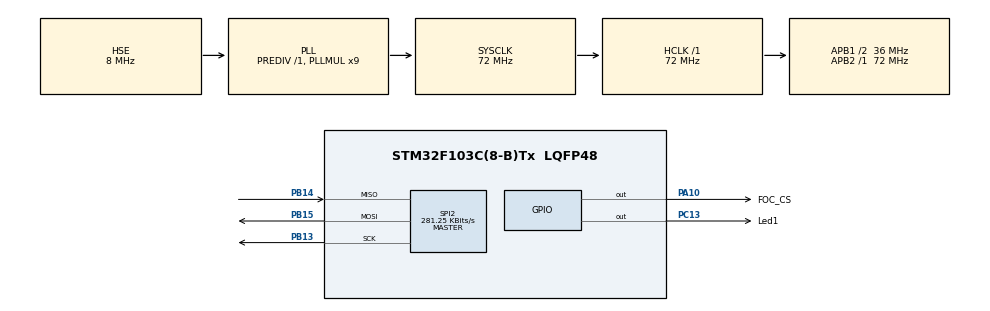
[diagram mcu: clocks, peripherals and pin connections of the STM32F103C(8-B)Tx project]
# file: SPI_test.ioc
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Mcu.Family=STM32F1
Mcu.Name=STM32F103C(8-B)Tx
Mcu.Package=LQFP48
NVIC.PriorityGroup=NVIC_PRIORITYGROUP_4
PA10.GPIO_Label=FOC_CS
PA10.Signal=GPIO_Output
PA13.Mode=Trace_Asynchronous_SW
PA13.Signal=SYS_JTMS-SWDIO
PA14.Mode=Trace_Asynchronous_SW
PA14.Signal=SYS_JTCK-SWCLK
PB13.Mode=Full_Duplex_Master
PB13.Signal=SPI2_SCK
PB14.Mode=Full_Duplex_Master
PB14.Signal=SPI2_MISO
PB15.Mode=Full_Duplex_Master
PB15.Signal=SPI2_MOSI
PB3.Mode=Trace_Asynchronous_SW
PB3.Signal=SYS_JTDO-TRACESWO
PC13-TAMPER-RTC.GPIO_Label=Led1
PC13-TAMPER-RTC.Signal=GPIO_Output
PC14-OSC32_IN.Mode=LSE-External-Oscillator
PC14-OSC32_IN.Signal=RCC_OSC32_IN
PC15-OSC32_OUT.Mode=LSE-External-Oscillator
PC15-OSC32_OUT.Signal=RCC_OSC32_OUT
PD0-OSC_IN.Mode=HSE-External-Oscillator
PD0-OSC_IN.Signal=RCC_OSC_IN
PD1-OSC_OUT.Mode=HSE-External-Oscillator
PD1-OSC_OUT.Signal=RCC_OSC_OUT
ProjectManager.HeapSize=0x200
ProjectManager.StackSize=0x400
ProjectManager.TargetToolchain=STM32CubeIDE
RCC.AHBFreq_Value=72000000
RCC.APB1CLKDivider=RCC_HCLK_DIV2
RCC.APB1Freq_Value=36000000
RCC.APB1TimFreq_Value=72000000
RCC.APB2Freq_Value=72000000
RCC.APB2TimFreq_Value=72000000
RCC.HCLKFreq_Value=72000000
RCC.PLLMUL=RCC_PLL_MUL9
RCC.PLLSourceVirtual=RCC_PLLSOURCE_HSE
RCC.SYSCLKFreq_VALUE=72000000
RCC.SYSCLKSource=RCC_SYSCLKSOURCE_PLLCLK
RCC.USBFreq_Value=72000000
SPI2.BaudRatePrescaler=SPI_BAUDRATEPRESCALER_128
SPI2.CLKPhase=SPI_PHASE_2EDGE
SPI2.CLKPolarity=SPI_POLARITY_HIGH
SPI2.CalculateBaudRate=281.25 KBits/s
SPI2.Direction=SPI_DIRECTION_2LINES
SPI2.Mode=SPI_MODE_MASTER
SPI2.VirtualType=VM_MASTER
board=custom

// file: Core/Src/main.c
/* USER CODE BEGIN Header */
/**
  ******************************************************************************
  * @file           : main.c
  * @brief          : Main program body
  ******************************************************************************
  * @attention
  *
  * <h2><center>&copy; Copyright (c) 2020 STMicroelectronics.
  * All rights reserved.</center></h2>
  *
  * This software component is licensed by ST under BSD 3-Clause license,
  * the "License"; You may not use this file except in compliance with the
  * License. You may obtain a copy of the License at:
  *                        opensource.org/licenses/BSD-3-Clause
  *
  ******************************************************************************
  */
/* USER CODE END Header */

#include "main.h"

/* USER CODE BEGIN Includes */
#include <stdio.h>

/* USER CODE END Includes */

SPI_HandleTypeDef hspi2;

void SystemClock_Config(void);
static void MX_GPIO_Init(void);
static void MX_SPI2_Init(void);

int main(void)
{

  /* MCU Configuration--------------------------------------------------------*/

  /* Reset of all peripherals, Initializes the Flash interface and the Systick. */
  HAL_Init();

  /* USER CODE BEGIN Init */

  HAL_GPIO_WritePin(FOC_CS_GPIO_Port, FOC_CS_Pin, SET);
  /* USER CODE END Init */

  /* Configure the system clock */
  SystemClock_Config();

  /* Initialize all configured peripherals */
  MX_GPIO_Init();
  MX_SPI2_Init();
  /* USER CODE BEGIN 2 */
  uint8_t aux[5], aux2[1], str[5];
     aux[0]=0b10000001;
     for(int i=1; i<=4; i++){
   	  aux[i]=0b00000000;
     }
     aux2[0]=0b00000000;

  for(int i=0; i<4; i++){
  	  printf("aux %d - %d\n", i, aux[i]);
    }
  /* USER CODE END 2 */

  /* Infinite loop */
  while (1)
  {

    /* USER CODE BEGIN 3 */

	  HAL_GPIO_TogglePin(Led1_GPIO_Port, Led1_Pin);
	  HAL_Delay(50);

	  HAL_GPIO_WritePin(FOC_CS_GPIO_Port, FOC_CS_Pin, RESET);
	  HAL_SPI_Transmit(&hspi2, aux, 5, 1000);
	  HAL_GPIO_WritePin(FOC_CS_GPIO_Port, FOC_CS_Pin, SET);
	  //HAL_Delay(1);

	  HAL_GPIO_WritePin(FOC_CS_GPIO_Port, FOC_CS_Pin, RESET);
	  HAL_SPI_Transmit(&hspi2, aux2, 1, 1000);
	  //HAL_Delay(1);
	  HAL_SPI_Receive(&hspi2, str, 4, 1000);
	  HAL_GPIO_WritePin(FOC_CS_GPIO_Port, FOC_CS_Pin, SET);
	  //HAL_SPI_Receive(&hspi2, str, 4, 200);
	  printf("Aquiii\n");
	  printf("%d %d %d %d\n", str[0], str[1], str[2], str[3]);

  }
  /* USER CODE END 3 */
}

void SystemClock_Config(void)
{
  RCC_OscInitTypeDef RCC_OscInitStruct = {0};
  RCC_ClkInitTypeDef RCC_ClkInitStruct = {0};

  /** Initializes the CPU, AHB and APB busses clocks
  */
  RCC_OscInitStruct.OscillatorType = RCC_OSCILLATORTYPE_HSE;
  RCC_OscInitStruct.HSEState = RCC_HSE_ON;
  RCC_OscInitStruct.HSEPredivValue = RCC_HSE_PREDIV_DIV1;
  RCC_OscInitStruct.HSIState = RCC_HSI_ON;
  RCC_OscInitStruct.PLL.PLLState = RCC_PLL_ON;
  RCC_OscInitStruct.PLL.PLLSource = RCC_PLLSOURCE_HSE;
  RCC_OscInitStruct.PLL.PLLMUL = RCC_PLL_MUL9;
  if (HAL_RCC_OscConfig(&RCC_OscInitStruct) != HAL_OK)
  {
    Error_Handler();
  }
  /** Initializes the CPU, AHB and APB busses clocks
  */
  RCC_ClkInitStruct.ClockType = RCC_CLOCKTYPE_HCLK|RCC_CLOCKTYPE_SYSCLK
                              |RCC_CLOCKTYPE_PCLK1|RCC_CLOCKTYPE_PCLK2;
  RCC_ClkInitStruct.SYSCLKSource = RCC_SYSCLKSOURCE_PLLCLK;
  RCC_ClkInitStruct.AHBCLKDivider = RCC_SYSCLK_DIV1;
  RCC_ClkInitStruct.APB1CLKDivider = RCC_HCLK_DIV2;
  RCC_ClkInitStruct.APB2CLKDivider = RCC_HCLK_DIV1;

  if (HAL_RCC_ClockConfig(&RCC_ClkInitStruct, FLASH_LATENCY_2) != HAL_OK)
  {
    Error_Handler();
  }
}

static void MX_SPI2_Init(void)
{

  /* SPI2 parameter configuration*/
  hspi2.Instance = SPI2;
  hspi2.Init.Mode = SPI_MODE_MASTER;
  hspi2.Init.Direction = SPI_DIRECTION_2LINES;
  hspi2.Init.DataSize = SPI_DATASIZE_8BIT;
  hspi2.Init.CLKPolarity = SPI_POLARITY_HIGH;
  hspi2.Init.CLKPhase = SPI_PHASE_2EDGE;
  hspi2.Init.NSS = SPI_NSS_SOFT;
  hspi2.Init.BaudRatePrescaler = SPI_BAUDRATEPRESCALER_128;
  hspi2.Init.FirstBit = SPI_FIRSTBIT_MSB;
  hspi2.Init.TIMode = SPI_TIMODE_DISABLE;
  hspi2.Init.CRCCalculation = SPI_CRCCALCULATION_DISABLE;
  hspi2.Init.CRCPolynomial = 10;
  if (HAL_SPI_Init(&hspi2) != HAL_OK)
  {
    Error_Handler();
  }

}

static void MX_GPIO_Init(void)
{
  GPIO_InitTypeDef GPIO_InitStruct = {0};

  /* GPIO Ports Clock Enable */
  __HAL_RCC_GPIOC_CLK_ENABLE();
  __HAL_RCC_GPIOD_CLK_ENABLE();
  __HAL_RCC_GPIOB_CLK_ENABLE();
  __HAL_RCC_GPIOA_CLK_ENABLE();

  /*Configure GPIO pin Output Level */
  HAL_GPIO_WritePin(Led1_GPIO_Port, Led1_Pin, GPIO_PIN_RESET);

  /*Configure GPIO pin Output Level */
  HAL_GPIO_WritePin(FOC_CS_GPIO_Port, FOC_CS_Pin, GPIO_PIN_RESET);

  /*Configure GPIO pin : Led1_Pin */
  GPIO_InitStruct.Pin = Led1_Pin;
  GPIO_InitStruct.Mode = GPIO_MODE_OUTPUT_PP;
  GPIO_InitStruct.Pull = GPIO_NOPULL;
  GPIO_InitStruct.Speed = GPIO_SPEED_FREQ_LOW;
  HAL_GPIO_Init(Led1_GPIO_Port, &GPIO_InitStruct);

  /*Configure GPIO pin : FOC_CS_Pin */
  GPIO_InitStruct.Pin = FOC_CS_Pin;
  GPIO_InitStruct.Mode = GPIO_MODE_OUTPUT_PP;
  GPIO_InitStruct.Pull = GPIO_NOPULL;
  GPIO_InitStruct.Speed = GPIO_SPEED_FREQ_LOW;
  HAL_GPIO_Init(FOC_CS_GPIO_Port, &GPIO_InitStruct);

}

/* USER CODE BEGIN 4 */
int __io_putchar(int ch){
	ITM_SendChar(ch);
	return ch;
}

int _write(int file, char *ptr, int len){
	int DataIdx;

	for(DataIdx = 0; DataIdx < len; DataIdx++){
		__io_putchar(*ptr++);
	}
	return len;
}
/* USER CODE END 4 */

void Error_Handler(void)
{
}

/************************ (C) COPYRIGHT STMicroelectronics *****END OF FILE****/
